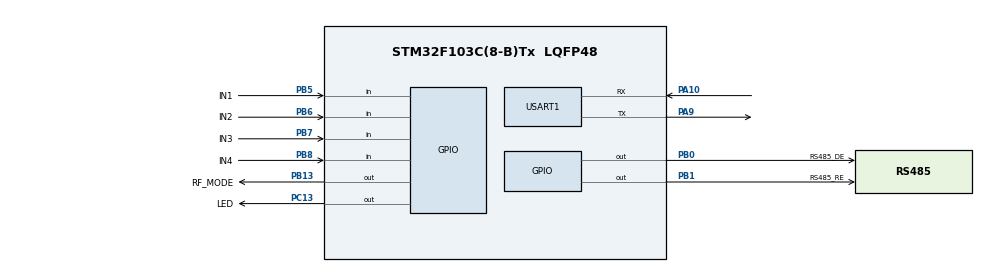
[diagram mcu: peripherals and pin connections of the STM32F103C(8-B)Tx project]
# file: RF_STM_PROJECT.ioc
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Mcu.Family=STM32F1
Mcu.Name=STM32F103C(8-B)Tx
Mcu.Package=LQFP48
NVIC.PriorityGroup=NVIC_PRIORITYGROUP_4
NVIC.USART1_IRQn=true\:0\:0\:false\:false\:true\:true\:true\:true
PA10.Mode=Asynchronous
PA10.Signal=USART1_RX
PA13.Mode=Serial_Wire
PA13.Signal=SYS_JTMS-SWDIO
PA14.Mode=Serial_Wire
PA14.Signal=SYS_JTCK-SWCLK
PA9.Mode=Asynchronous
PA9.Signal=USART1_TX
PB0.GPIO_Label=RS485_DE
PB0.Signal=GPIO_Output
PB1.GPIO_Label=RS485_RE
PB1.Signal=GPIO_Output
PB13.GPIO_Label=RF_MODE
PB13.Signal=GPIO_Output
PB5.GPIO_Label=IN1
PB5.GPIO_PuPd=GPIO_PULLDOWN
PB5.Signal=GPIO_Input
PB6.GPIO_Label=IN2
PB6.GPIO_PuPd=GPIO_PULLDOWN
PB6.Signal=GPIO_Input
PB7.GPIO_Label=IN3
PB7.GPIO_PuPd=GPIO_PULLDOWN
PB7.Signal=GPIO_Input
PB8.GPIO_Label=IN4
PB8.GPIO_PuPd=GPIO_PULLDOWN
PB8.Signal=GPIO_Input
PC13-TAMPER-RTC.GPIO_Label=LED
PC13-TAMPER-RTC.Signal=GPIO_Output
PD0-OSC_IN.Mode=HSE-External-Oscillator
PD0-OSC_IN.Signal=RCC_OSC_IN
PD1-OSC_OUT.Mode=HSE-External-Oscillator
PD1-OSC_OUT.Signal=RCC_OSC_OUT
ProjectManager.HeapSize=0x200
ProjectManager.StackSize=0x400
ProjectManager.TargetToolchain=STM32CubeIDE
RCC.APB1Freq_Value=8000000
RCC.APB2Freq_Value=8000000
USART1.VirtualMode=VM_ASYNC
board=custom

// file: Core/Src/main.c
/* USER CODE BEGIN Header */
/**
  ******************************************************************************
  * @file           : main.c
  * @brief          : Main program body
  ******************************************************************************
  * @attention
  *
  * Copyright (c) 2026 STMicroelectronics.
  * All rights reserved.
  *
  * This software is licensed under terms that can be found in the LICENSE file
  * in the root directory of this software component.
  * If no LICENSE file comes with this software, it is provided AS-IS.
  *
  ******************************************************************************
  */
/* USER CODE END Header */
#include "main.h"
#include "Isolated_Input.h"
#include "max485.h"
#include "uart.h"
#include "string.h"
#include "stdio.h"
#include "protocol.h"

UART_HandleTypeDef huart1;

void SystemClock_Config(void);
static void MX_GPIO_Init(void);
static void MX_USART1_UART_Init(void);

/* USER CODE BEGIN 0 */
/* USER CODE BEGIN 0 */

void Check_4Input(void)
{
    uint8_t State[4];

    Input_GetAll(State);

    if (State[0] || State[1] || State[2] || State[3])
    {
        HAL_GPIO_WritePin(LED_GPIO_Port, LED_Pin, GPIO_PIN_RESET);
    }
    else
    {
        HAL_GPIO_WritePin(LED_GPIO_Port, LED_Pin, GPIO_PIN_SET);
    }
}
/* USER CODE END 0 */
/* USER CODE END 0 */

int main(void)
{

  /* MCU Configuration--------------------------------------------------------*/

  /* Reset of all peripherals, Initializes the Flash interface and the Systick. */
  HAL_Init();

  /* Configure the system clock */
  SystemClock_Config();

  /* Initialize all configured peripherals */
  MX_GPIO_Init();
  MX_USART1_UART_Init();

  MAX485_Init(&huart1);

  /* Load config 1 lần khi vừa boot */
  Config_LoadFromFlash();

  MAX485_SendString("RS485 READY\r\n");

  while (1)
  {
      Check_4Input();

      if (MAX485_Available())
      {
          char *cmd;

          cmd = MAX485_ReadLine();

          if (cmd != NULL)
          {
              Protocol_Process(cmd);
          }
      }

      HAL_Delay(10);
  }
  /* USER CODE END 3 */
}

void SystemClock_Config(void)
{
  RCC_OscInitTypeDef RCC_OscInitStruct = {0};
  RCC_ClkInitTypeDef RCC_ClkInitStruct = {0};

  /** Initializes the RCC Oscillators according to the specified parameters
  * in the RCC_OscInitTypeDef structure.
  */
  RCC_OscInitStruct.OscillatorType = RCC_OSCILLATORTYPE_HSI;
  RCC_OscInitStruct.HSIState = RCC_HSI_ON;
  RCC_OscInitStruct.HSICalibrationValue = RCC_HSICALIBRATION_DEFAULT;
  RCC_OscInitStruct.PLL.PLLState = RCC_PLL_NONE;
  if (HAL_RCC_OscConfig(&RCC_OscInitStruct) != HAL_OK)
  {
    Error_Handler();
  }

  /** Initializes the CPU, AHB and APB buses clocks
  */
  RCC_ClkInitStruct.ClockType = RCC_CLOCKTYPE_HCLK|RCC_CLOCKTYPE_SYSCLK
                              |RCC_CLOCKTYPE_PCLK1|RCC_CLOCKTYPE_PCLK2;
  RCC_ClkInitStruct.SYSCLKSource = RCC_SYSCLKSOURCE_HSI;
  RCC_ClkInitStruct.AHBCLKDivider = RCC_SYSCLK_DIV1;
  RCC_ClkInitStruct.APB1CLKDivider = RCC_HCLK_DIV1;
  RCC_ClkInitStruct.APB2CLKDivider = RCC_HCLK_DIV1;

  if (HAL_RCC_ClockConfig(&RCC_ClkInitStruct, FLASH_LATENCY_0) != HAL_OK)
  {
    Error_Handler();
  }
}

static void MX_USART1_UART_Init(void)
{

  huart1.Instance = USART1;
  huart1.Init.BaudRate = 115200;
  huart1.Init.WordLength = UART_WORDLENGTH_8B;
  huart1.Init.StopBits = UART_STOPBITS_1;
  huart1.Init.Parity = UART_PARITY_NONE;
  huart1.Init.Mode = UART_MODE_TX_RX;
  huart1.Init.HwFlowCtl = UART_HWCONTROL_NONE;
  huart1.Init.OverSampling = UART_OVERSAMPLING_16;
  if (HAL_UART_Init(&huart1) != HAL_OK)
  {
    Error_Handler();
  }

}

static void MX_GPIO_Init(void)
{
  GPIO_InitTypeDef GPIO_InitStruct = {0};

  /* GPIO Ports Clock Enable */
  __HAL_RCC_GPIOC_CLK_ENABLE();
  __HAL_RCC_GPIOD_CLK_ENABLE();
  __HAL_RCC_GPIOB_CLK_ENABLE();
  __HAL_RCC_GPIOA_CLK_ENABLE();

  /*Configure GPIO pin Output Level */
  HAL_GPIO_WritePin(LED_GPIO_Port, LED_Pin, GPIO_PIN_RESET);

  /*Configure GPIO pin Output Level */
  HAL_GPIO_WritePin(GPIOB, RS485_DE_Pin|RS485_RE_Pin|RF_MODE_Pin, GPIO_PIN_RESET);

  /*Configure GPIO pin : LED_Pin */
  GPIO_InitStruct.Pin = LED_Pin;
  GPIO_InitStruct.Mode = GPIO_MODE_OUTPUT_PP;
  GPIO_InitStruct.Pull = GPIO_NOPULL;
  GPIO_InitStruct.Speed = GPIO_SPEED_FREQ_LOW;
  HAL_GPIO_Init(LED_GPIO_Port, &GPIO_InitStruct);

  /*Configure GPIO pins : RS485_DE_Pin RS485_RE_Pin RF_MODE_Pin */
  GPIO_InitStruct.Pin = RS485_DE_Pin|RS485_RE_Pin|RF_MODE_Pin;
  GPIO_InitStruct.Mode = GPIO_MODE_OUTPUT_PP;
  GPIO_InitStruct.Pull = GPIO_NOPULL;
  GPIO_InitStruct.Speed = GPIO_SPEED_FREQ_LOW;
  HAL_GPIO_Init(GPIOB, &GPIO_InitStruct);

  /*Configure GPIO pins : IN1_Pin IN2_Pin IN3_Pin IN4_Pin */
  GPIO_InitStruct.Pin = IN1_Pin|IN2_Pin|IN3_Pin|IN4_Pin;
  GPIO_InitStruct.Mode = GPIO_MODE_INPUT;
  GPIO_InitStruct.Pull = GPIO_PULLDOWN;
  HAL_GPIO_Init(GPIOB, &GPIO_InitStruct);

}

/* USER CODE BEGIN 4 */
void HAL_UART_RxCpltCallback(UART_HandleTypeDef *huart)
{
    MAX485_UART_Callback(huart);
}
/* USER CODE END 4 */

void Error_Handler(void)
{
  __disable_irq();
  while (1)
  {
  }
}
